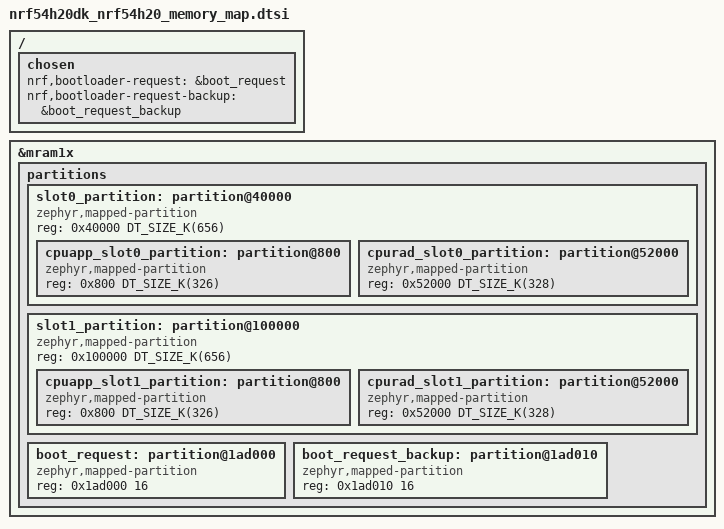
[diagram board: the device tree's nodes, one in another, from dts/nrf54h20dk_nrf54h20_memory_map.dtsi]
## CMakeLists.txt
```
#
# Copyright (c) 2025 Nordic Semiconductor ASA
#
# SPDX-License-Identifier: LicenseRef-Nordic-5-Clause
#


cmake_minimum_required(VERSION 3.20.0)

find_package(Zephyr REQUIRED HINTS $ENV{ZEPHYR_BASE})
project(ab)

target_sources(app PRIVATE src/main.c)
target_sources(app PRIVATE src/ab_utils.c)

target_include_directories(
    app PRIVATE
    ${ZEPHYR_MCUBOOT_MODULE_DIR}/boot/bootutil/include
    ${ZEPHYR_MCUBOOT_MODULE_DIR}/boot/zephyr/include
    ${ZEPHYR_BASE}/samples/subsys/mgmt/mcumgr/smp_svr/src
  )

target_sources_ifdef(CONFIG_MCUMGR_TRANSPORT_BT app PRIVATE
                     ${ZEPHYR_BASE}/samples/subsys/mgmt/mcumgr/smp_svr/src/bluetooth.c)
```

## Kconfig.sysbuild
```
#
# Copyright (c) 2025 Nordic Semiconductor ASA
#
# SPDX-License-Identifier: LicenseRef-Nordic-5-Clause
#

if SOC_SERIES_NRF54H

# Enable radiocore
config NRF_DEFAULT_IPC_RADIO
	default y

config NETCORE_IPC_RADIO_BT_HCI_IPC
	default y

config MCUBOOT_IMAGES_ROM_END_OFFSET_AUTO
	default "ipc_radio;ipc_radio_secondary_app"

endif # SOC_SERIES_NRF54H

source "share/sysbuild/Kconfig"
```

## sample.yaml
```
sample:
  description: AB update sample
  name: ab
common:
  sysbuild: true
  build_only: true
  tags:
    - dfu_ab
    - ci_samples_dfu

tests:
  sample.dfu.ab:
    platform_allow:
      - nrf54h20dk/nrf54h20/cpuapp
      - nrf54l15dk/nrf54l15/cpuapp
    integration_platforms:
      - nrf54h20dk/nrf54h20/cpuapp
      - nrf54l15dk/nrf54l15/cpuapp

  sample.dfu.ab.s2ram:
    extra_args:
      - mcuboot_CONFIG_SOC_EARLY_RESET_HOOK=y
      - CONFIG_PM=y
      - CONFIG_PM_DEVICE=y
      - CONFIG_PM_DEVICE_RUNTIME=y
      - CONFIG_POWEROFF=y
    platform_allow:
      - nrf54h20dk/nrf54h20/cpuapp
    integration_platforms:
      - nrf54h20dk/nrf54h20/cpuapp

  sample.dfu.ab.ironside_se_conf:
    platform_allow:
      - nrf54h20dk/nrf54h20/cpuapp
    integration_platforms:
      - nrf54h20dk/nrf54h20/cpuapp
    extra_args:
      - FILE_SUFFIX=ironside_se_conf
```

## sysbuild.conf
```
# Enable MCUboot bootloader support
SB_CONFIG_BOOTLOADER_MCUBOOT=y

# Enable direct XIP with revert support
SB_CONFIG_MCUBOOT_MODE_DIRECT_XIP_WITH_REVERT=y
```

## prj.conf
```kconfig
# Enable MCUmgr and dependencies.
CONFIG_NET_BUF=y
CONFIG_ZCBOR=y
CONFIG_CRC=y
CONFIG_MCUMGR=y
CONFIG_STREAM_FLASH=y
CONFIG_FLASH_MAP=y

# Some command handlers require a large stack.
CONFIG_SYSTEM_WORKQUEUE_STACK_SIZE=2304
CONFIG_MAIN_STACK_SIZE=2176

# Ensure an MCUboot-compatible binary is generated.
CONFIG_BOOTLOADER_MCUBOOT=y

# Enable flash operations.
CONFIG_FLASH=y

# Required by the `taskstat` command.
CONFIG_THREAD_MONITOR=y

# Support for taskstat command
CONFIG_MCUMGR_GRP_OS_TASKSTAT=y

# Enable statistics and statistic names.
CONFIG_STATS=y
CONFIG_STATS_NAMES=y

# Enable most core commands.
CONFIG_FLASH=y
CONFIG_IMG_MANAGER=y
CONFIG_MCUMGR_GRP_IMG=y
CONFIG_MCUMGR_GRP_IMG_NRF=y
CONFIG_MCUMGR_GRP_OS=y
CONFIG_MCUMGR_GRP_STAT=y

# Enable logging
CONFIG_LOG=y
CONFIG_MCUBOOT_UTIL_LOG_LEVEL_WRN=y

# Disable debug logging
CONFIG_LOG_MAX_LEVEL=3

# Enable boot requests.
CONFIG_NRF_MCUBOOT_BOOT_REQUEST=y

# Enable DK LED/button library
CONFIG_DK_LIBRARY=y

# Configure bluetooth

CONFIG_BT=y
CONFIG_BT_PERIPHERAL=y

# Allow for large Bluetooth data packets.
CONFIG_BT_L2CAP_TX_MTU=498
CONFIG_BT_BUF_ACL_RX_SIZE=502
CONFIG_BT_BUF_ACL_TX_SIZE=502

# Enable the Bluetooth mcumgr transport (unauthenticated).
CONFIG_MCUMGR_TRANSPORT_BT=y
CONFIG_MCUMGR_TRANSPORT_BT_CONN_PARAM_CONTROL=y

# Enable the Shell mcumgr transport.
CONFIG_BASE64=y
CONFIG_CRC=y
CONFIG_SHELL=y
CONFIG_SHELL_BACKEND_SERIAL=y
CONFIG_MCUMGR_TRANSPORT_SHELL=y

# Enable the mcumgr Packet Reassembly feature over Bluetooth and its configuration dependencies.
# MCUmgr buffer size is optimized to fit one SMP packet divided into five Bluetooth Write Commands,
# transmitted with the maximum possible MTU value: 498 bytes.
CONFIG_MCUMGR_TRANSPORT_BT_REASSEMBLY=y
CONFIG_MCUMGR_TRANSPORT_NETBUF_SIZE=2475
CONFIG_MCUMGR_GRP_OS_MCUMGR_PARAMS=y
CONFIG_MCUMGR_TRANSPORT_WORKQUEUE_STACK_SIZE=4608

# Enable the LittleFS file system.
CONFIG_FILE_SYSTEM=y
CONFIG_FILE_SYSTEM_LITTLEFS=y

# Enable file system commands
CONFIG_MCUMGR_GRP_FS=y

# Enable the storage erase command.
CONFIG_MCUMGR_GRP_ZBASIC=y
CONFIG_MCUMGR_GRP_ZBASIC_STORAGE_ERASE=y

# Disable Bluetooth ping support
CONFIG_BT_CTLR_LE_PING=n

# Disable shell commands that are not needed
CONFIG_CLOCK_CONTROL_NRF_SHELL=n
CONFIG_DEVICE_SHELL=n
CONFIG_DEVMEM_SHELL=n
CONFIG_FLASH_SHELL=n
```

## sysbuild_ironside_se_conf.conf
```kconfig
# Enable MCUboot bootloader support
SB_CONFIG_BOOTLOADER_MCUBOOT=y

# Enable direct XIP with revert support
SB_CONFIG_MCUBOOT_MODE_DIRECT_XIP_WITH_REVERT=y

SB_CONFIG_NCS_MCUBOOT_LOAD_PERIPHCONF=y
SB_CONFIG_NCS_MCUBOOT_MPCCONF_STATIC_WRITE_PROTECTION=y
```

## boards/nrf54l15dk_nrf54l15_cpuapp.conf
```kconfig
# Enable boot requests through retained memory.
CONFIG_RETAINED_MEM=y
CONFIG_RETENTION=y
```

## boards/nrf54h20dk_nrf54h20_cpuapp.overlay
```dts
/*
 * Copyright (c) 2025 Nordic Semiconductor ASA
 *
 * SPDX-License-Identifier: LicenseRef-Nordic-5-Clause
 */

#include "../dts/nrf54h20dk_nrf54h20_memory_map.dtsi"

/ {
	chosen {
		zephyr,boot-mode = &boot_request;
	};
};

secondary_app_partition: &cpuapp_slot1_partition {};
```

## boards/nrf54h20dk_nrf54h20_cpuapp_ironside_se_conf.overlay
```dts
/*
 * Copyright (c) 2026 Nordic Semiconductor ASA
 *
 * SPDX-License-Identifier: LicenseRef-Nordic-5-Clause
 */

#include "../dts/nrf54h20dk_nrf54h20_memory_map.dtsi"
#include "../dts/nrf54h20dk_nrf54h20_memory_map_ironside_se_conf.dtsi"

/ {
	chosen {
		zephyr,boot-mode = &boot_request;
	};
};

secondary_app_partition: &cpuapp_slot1_partition {};
```

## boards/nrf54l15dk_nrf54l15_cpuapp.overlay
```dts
/*
 * Copyright (c) 2025 - 2026 Nordic Semiconductor ASA
 *
 * SPDX-License-Identifier: LicenseRef-Nordic-5-Clause
 */

/ {
	chosen {
		nrf,bootloader-request = &boot_request;
	};
};

/ {
	cpuapp_sram@2003fff0 {
		compatible = "zephyr,memory-region", "mmio-sram";
		reg = <0x2003fff0 0x10>;
		zephyr,memory-region = "RetainedMem";
		status = "okay";

		retainedmem {
			compatible = "zephyr,retained-ram";
			status = "okay";
			#address-cells = <1>;
			#size-cells = <1>;

			boot_request: boot_request@0 {
				compatible = "zephyr,retention";
				status = "okay";
				reg = <0x0 0x10>;
				prefix = [0b 01];
				checksum = <4>;
			};
		};
	};
};

/delete-node/ &boot_partition;
/delete-node/ &slot0_partition;
/delete-node/ &slot1_partition;
/delete-node/ &storage_partition;

&cpuapp_rram {
	partitions {
		boot_partition: partition@0 {
			compatible = "zephyr,mapped-partition";
			label = "mcuboot";
			reg = <0x0 0x10800>;
		};

		slot0_partition: partition@11000 {
			compatible = "zephyr,mapped-partition";
			label = "image-0";
			reg = <0x11000 0xb3000>;
		};

		slot1_partition: partition@c4000 {
			compatible = "zephyr,mapped-partition";
			label = "image-1";
			reg = <0xc4000 0xb3000>;
		};

		littlefs_storage: storage_partition: partition@177000 {
			compatible = "zephyr,mapped-partition";
			label = "littlefs-storage";
			reg = <0x177000 0x6000>;
		};
	};
};
```

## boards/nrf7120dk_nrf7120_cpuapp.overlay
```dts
/*
 * Copyright (c) 2026 Nordic Semiconductor ASA
 *
 * SPDX-License-Identifier: LicenseRef-Nordic-5-Clause
 */

#include "../dts/nrf7120dk_nrf7120_cpuapp_common.dtsi"

secondary_app_partition: &slot1_partition {};
```

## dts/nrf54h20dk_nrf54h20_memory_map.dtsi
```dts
/*
 * Copyright (c) 2025 Nordic Semiconductor ASA
 *
 * SPDX-License-Identifier: LicenseRef-Nordic-5-Clause
 */

/* On nRF54H20 the Direct XIP mode is supported in the merged slot configuration
 * Extend slot0_partition and slot1_partition to cover both application and
 * radio images, as well as MCUboot image metadata (header and trailer).
 * Those partitions will be used by MCUboot to verify the merged image to boot.
 * Apart from that, they will be used by the MCUmgr subsystem to correctly
 * handle flags, stored inside the MCUboot image trailer.
 * Use cpu<app|rad>_slot<0|1>_partition as zephyr,code-partition, so the
 * application and radio sizes are correctly reported.
 */
/delete-node/ &cpuapp_slot0_partition;
/delete-node/ &cpuapp_slot1_partition;
/delete-node/ &cpurad_slot0_partition;
/delete-node/ &cpurad_slot1_partition;

&mram1x {
	partitions {
		/* Merged partition used by the MCUboot (variant 0). */
		slot0_partition: partition@40000 {
			compatible = "zephyr,mapped-partition";
			reg = <0x40000 DT_SIZE_K(656)>;
			ranges = <0x0 0x40000 DT_SIZE_K(656)>;
			#address-cells = <1>;
			#size-cells = <1>;

			/* Application code partition (variant 0).
			 * Offset by the MCUboot header size (2048 bytes).
			 */
			cpuapp_slot0_partition: partition@800 {
				compatible = "zephyr,mapped-partition";
				reg = <0x800 DT_SIZE_K(326)>;
			};

			/* Radio code partition (variant 0). */
			cpurad_slot0_partition: partition@52000 {
				compatible = "zephyr,mapped-partition";
				reg = <0x52000 DT_SIZE_K(328)>;
			};
		};

		/* Merged partition used by the MCUboot (variant 1). */
		slot1_partition: partition@100000 {
			compatible = "zephyr,mapped-partition";
			reg = <0x100000 DT_SIZE_K(656)>;
			ranges = <0x0 0x100000 DT_SIZE_K(656)>;
			#address-cells = <1>;
			#size-cells = <1>;

			/* Application code partition (variant 1).
			 * Offset by the MCUboot header size (2048 bytes).
			 */
			cpuapp_slot1_partition: partition@800 {
				compatible = "zephyr,mapped-partition";
				reg = <0x800 DT_SIZE_K(326)>;
			};

			/* Radio code partition (variant 1). */
			cpurad_slot1_partition: partition@52000 {
				compatible = "zephyr,mapped-partition";
				reg = <0x52000 DT_SIZE_K(328)>;
			};
		};

		boot_request: partition@1ad000 {
			compatible = "zephyr,mapped-partition";
			reg = <0x1ad000 16>;
		};

		boot_request_backup: partition@1ad010 {
			compatible = "zephyr,mapped-partition";
			reg = <0x1ad010 16>;
		};
	};
};

/ {
	chosen {
		nrf,bootloader-request = &boot_request;
		nrf,bootloader-request-backup = &boot_request_backup;
	};
};
```

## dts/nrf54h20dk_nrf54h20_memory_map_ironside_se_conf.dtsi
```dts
/*
 * Copyright (c) 2026 Nordic Semiconductor ASA
 *
 * SPDX-License-Identifier: LicenseRef-Nordic-5-Clause
 */

/delete-node/ &cpuapp_boot_partition;
/delete-node/ &mpcconf_partition;
/delete-node/ &periphconf_partition;

&mram1x {
	partitions {
		/* UICR.PROTECTEDMEM region */
		protectedmem_partition: partition@30000 {
			compatible = "zephyr,mapped-partition";
			reg = <0x30000 DT_SIZE_K(64)>;
			#address-cells = <1>;
			#size-cells = <1>;
			ranges = <0x0 0x30000 DT_SIZE_K(64)>;

			/* Update the boot partition to reserve
			 * the final 0.5 kB for PERIPHCONF/MPCCONF
			 */
			cpuapp_boot_partition: boot_partition: partition@30000 {
				compatible = "zephyr,mapped-partition";
				reg = <0x30000 (DT_SIZE_K(64) - 512)>;
			};

			/* UICR.MPCCONF blob. */
			mpcconf_partition: partition@3fe00 {
				compatible = "zephyr,mapped-partition";
				reg = <0x3fe00 48>;
			};

			/* UICR.PERIPHCONF blob (only used for MCUboot's configuration). */
			periphconf_partition: partition@3fe30 {
				compatible = "zephyr,mapped-partition";
				reg = <0x3fe30 464>;
			};
		};
	};
};
```

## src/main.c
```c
/*
 * Copyright (c) 2012-2014 Wind River Systems, Inc.
 * Copyright (c) 2020 Prevas A/S
 * Copyright (c) 2025 Nordic Semiconductor ASA
 *
 * SPDX-License-Identifier: LicenseRef-Nordic-5-Clause
 */

#include <zephyr/kernel.h>
#include <common.h>
#include "ab_utils.h"

#define LOG_LEVEL LOG_LEVEL_DBG
#include <zephyr/logging/log.h>
LOG_MODULE_REGISTER(ab_sample);

int main(void)
{
#ifdef CONFIG_MCUMGR_TRANSPORT_BT
	start_smp_bluetooth_adverts();
#endif

	/* Give BLE a moment to start up */
	k_sleep(K_MSEC(1000));

	ab_actions_perform();

	/* using __TIME__ ensure that a new binary will be built on every
	 * compile which is convenient when testing firmware upgrade.
	 */
	LOG_INF("build time: " __DATE__ " " __TIME__);

	/* The system work queue handles all incoming mcumgr requests.  Let the
	 * main thread idle while the mcumgr server runs.
	 */
	while (1) {
		k_sleep(K_MSEC(1000));
	}

	return 0;
}
```

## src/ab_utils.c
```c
/*
 * Copyright (c) 2025 Nordic Semiconductor ASA
 *
 * SPDX-License-Identifier: LicenseRef-Nordic-5-Clause
 */

#include <zephyr/kernel.h>
#include <zephyr/logging/log.h>
#include <zephyr/bluetooth/bluetooth.h>
#include <bootutil/bootutil_public.h>
#include <bootutil/boot_request.h>

#include <dk_buttons_and_leds.h>

LOG_MODULE_DECLARE(ab_sample);

#define ACTIVE_IMAGE 0

#define CODE_PARTITION DT_CHOSEN(zephyr_code_partition)
#define CODE_PARTITION_OFFSET PARTITION_NODE_OFFSET(CODE_PARTITION)

#define SLOT_A_PARTITION slot0_partition
#define SLOT_B_PARTITION slot1_partition

#define SLOT_A_OFFSET PARTITION_OFFSET(SLOT_A_PARTITION)
#define SLOT_B_OFFSET PARTITION_OFFSET(SLOT_B_PARTITION)
#define SLOT_A_SIZE   PARTITION_SIZE(SLOT_A_PARTITION)
#define SLOT_B_SIZE   PARTITION_SIZE(SLOT_B_PARTITION)

#define SLOT_A_FLASH_AREA_ID PARTITION_ID(SLOT_A_PARTITION)
#define SLOT_B_FLASH_AREA_ID PARTITION_ID(SLOT_B_PARTITION)

#define IS_SLOT_A                                                                                  \
	(CODE_PARTITION_OFFSET >= SLOT_A_OFFSET &&                                                 \
	 CODE_PARTITION_OFFSET < SLOT_A_OFFSET + SLOT_A_SIZE)
#define IS_SLOT_B                                                                                  \
	(CODE_PARTITION_OFFSET >= SLOT_B_OFFSET &&                                                 \
	 CODE_PARTITION_OFFSET < SLOT_B_OFFSET + SLOT_B_SIZE)

#define STATUS_LEDS_THREAD_STACK_SIZE 512
#define STATUS_LEDS_THREAD_PRIORITY (CONFIG_NUM_PREEMPT_PRIORITIES - 1)
K_THREAD_STACK_DEFINE(status_leds_thread_stack_area, STATUS_LEDS_THREAD_STACK_SIZE);

/** @brief Radio firmware self test
 *
 * @details
 * End-device specific self test should be implemented here.
 */
static bool radio_domain_healthy(void)
{
	return bt_is_ready();
}

/** @brief Application firmware self test
 *
 * @details
 * End-device specific self test should be implemented here. Enabling
 * CONFIG_EMULATE_APP_HEALTH_CHECK_FAILURE allows to emulate a faulty
 * firmware, unable to confirm its health, and ultimately to test
 * a rollback to previous firmware after the update.
 */
static bool app_domain_healthy(void)
{
	if (IS_ENABLED(CONFIG_EMULATE_APP_HEALTH_CHECK_FAILURE)) {
		return false;
	}

	return true;
}

static enum boot_slot active_boot_slot_get(void)
{
	enum boot_slot active_slot = BOOT_SLOT_NONE;

	if (IS_SLOT_A) {
		active_slot = BOOT_SLOT_PRIMARY;
	} else if (IS_SLOT_B) {
		active_slot = BOOT_SLOT_SECONDARY;
	} else {
		LOG_ERR("Cannot determine current slot");
	}

	return active_slot;
}

static bool slot_confirmed(enum boot_slot slot)
{
	struct boot_swap_state state;
	const struct flash_area *fa;
	int area_id = -1;
	char *img_set = NULL;
	bool confirmed = false;
	int ret;

	if (slot == BOOT_SLOT_PRIMARY) {
		img_set = "A";
		area_id = SLOT_A_FLASH_AREA_ID;
	} else if (slot == BOOT_SLOT_SECONDARY) {
		img_set = "B";
		area_id = SLOT_B_FLASH_AREA_ID;
	} else {
		LOG_ERR("Cannot determine slot to check for confirmation");
		return false;
	}

	if (flash_area_open(area_id, &fa) != 0) {
		LOG_ERR("Cannot open flash area for slot %s", img_set);
		return false;
	}

	ret = boot_read_swap_state(fa, &state);
	if (ret != 0) {
		LOG_ERR("Cannot read swap state for slot %s", img_set);
	} else if (state.image_ok == BOOT_FLAG_SET) {
		confirmed = true;
	} else {
		confirmed = false;
	}

	flash_area_close(fa);

	return confirmed;
}

static void device_healthcheck(void)
{
	int err;
	char *img_set = NULL;
	enum boot_slot active_slot = active_boot_slot_get();

	/* Confirming only in non-degraded boot states */
	if (active_slot == BOOT_SLOT_PRIMARY) {
		img_set = "A";
	} else if (active_slot == BOOT_SLOT_SECONDARY) {
		img_set = "B";
	} else {
		LOG_ERR("Cannot determine active slot for health check");
		return;
	}

	if (slot_confirmed(active_slot)) {
		LOG_INF("Slot %s already confirmed, no action needed", img_set);
		return;
	}

	LOG_INF("Testing image set %s...", img_set);

	bool healthy = true;

	if (!radio_domain_healthy()) {
		LOG_ERR("Radio domain is NOT healthy");
		healthy = false;
	}

	if (!app_domain_healthy()) {
		LOG_ERR("App domain is NOT healthy");
		healthy = false;
	}

	if (!healthy) {
		LOG_ERR("Reboot the device to try to boot from previous firmware");
		return;
	}

	LOG_INF("Confirming...");

	err = boot_request_confirm_slot(ACTIVE_IMAGE, active_slot);
	if (err == 0) {
		LOG_INF("Confirmed\n");
	} else {
		LOG_ERR("Failed to confirm, err: %d", err);
	}
}

static void select_slot_for_single_boot(enum boot_slot slot)
{
	int err = 0;
	char active_slot = (active_boot_slot_get() == BOOT_SLOT_PRIMARY) ? 'A' : 'B';

#ifdef CONFIG_NRF_MCUBOOT_BOOT_REQUEST_PREFERENCE_KEEP
	if (slot == BOOT_SLOT_PRIMARY) {
		LOG_INF("Switching slots (%c -> A)", active_slot);
	} else if (slot == BOOT_SLOT_SECONDARY) {
		LOG_INF("Switching slots (%c -> B)", active_slot);
	} else {
		LOG_ERR("Cannot determine active slot, cannot toggle");
		return;
	}
#else
	if (slot == BOOT_SLOT_PRIMARY) {
		LOG_INF("Temporarily switching slots (%c -> A)", active_slot);
	} else if (slot == BOOT_SLOT_SECONDARY) {
		LOG_INF("Temporarily switching slots (%c -> B)", active_slot);
	} else {
		LOG_ERR("Cannot determine active slot, cannot toggle");
		return;
	}
#endif

	err = boot_request_set_preferred_slot(ACTIVE_IMAGE, slot);
	if (err == 0) {
		LOG_INF("Slot toggled, restart the device to enforce");
	} else {
		LOG_ERR("Failed to toggle slots, err: %d", err);
	}
}

static void boot_state_report(void)
{
	enum boot_slot active_slot = active_boot_slot_get();

	if (active_slot == BOOT_SLOT_PRIMARY) {
		LOG_INF("Booted from slot A");
	} else if (active_slot == BOOT_SLOT_SECONDARY) {
		LOG_INF("Booted from slot B");
	} else {
		LOG_INF("Cannot determine active slot");
	}
}

static void button_handler(uint32_t button_state, uint32_t has_changed)
{
	if ((has_changed & DK_BTN1_MSK) && (button_state & DK_BTN1_MSK)) {
		select_slot_for_single_boot(BOOT_SLOT_PRIMARY);
	} else if ((has_changed & DK_BTN2_MSK) && (button_state & DK_BTN2_MSK)) {
		select_slot_for_single_boot(BOOT_SLOT_SECONDARY);
	}
}

struct k_thread status_leds_thread_data;

static void status_leds_thread_entry_point(void *p1, void *p2, void *p3)
{
	int blinking_led = DK_LED1;
	enum boot_slot active_slot = active_boot_slot_get();

	if (active_slot == BOOT_SLOT_PRIMARY) {
		blinking_led = DK_LED1;
	} else if (active_slot == BOOT_SLOT_SECONDARY) {
		blinking_led = DK_LED2;
	} else {
		return;
	}

	while (1) {
		for (int i = 0; i < CONFIG_N_BLINKS; i++) {
			dk_set_led_off(blinking_led);
			k_msleep(250);
			dk_set_led_on(blinking_led);
			k_msleep(250);
		}

		k_msleep(5000);
	}
}

void ab_actions_perform(void)
{
	int ret;

	boot_state_report();

	ret = dk_leds_init();
	if (ret) {
		LOG_ERR("Cannot init LEDs (err: %d)", ret);
	}

	ret = dk_buttons_init(button_handler);
	if (ret) {
		LOG_ERR("Cannot init buttons (err: %d)", ret);
	}

	k_thread_create(&status_leds_thread_data, status_leds_thread_stack_area,
			K_THREAD_STACK_SIZEOF(status_leds_thread_stack_area),
			status_leds_thread_entry_point,
			NULL, NULL, NULL,
			STATUS_LEDS_THREAD_PRIORITY, 0, K_NO_WAIT);

	device_healthcheck();
}
```
